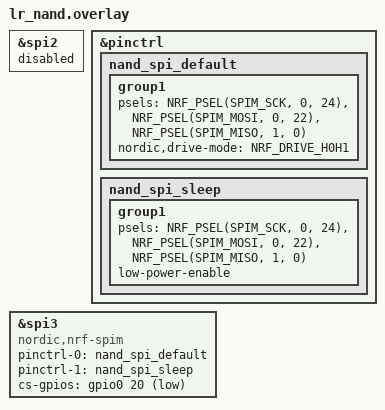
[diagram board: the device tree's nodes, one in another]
/* CONFIG_LR_NAND boards (LR-N5, LR-N5-S; a ProMicro on a breadboard for tests): a bare SPI NAND, W25N01GV or
 * W25N02KV (WSON-8 8x6), in place of the SD card, applied after the board's overlays (docs/nand-store.md 8, 11).
 * The chip on SPIM3 (EasyDMA, up to 32 MHz; SPIM0-2 stop at 8), on the SD card's four pins until the N5 pin plan
 * settles: CS P0.20, MOSI (DI) P0.22, SCK P0.24, MISO (DO) P1.00, all full-speed pins. SCK and MOSI at high drive
 * (H0H1): the nRF52840 PS asks for it above 8 MHz. Its supply: the SD card's LDO (sd-pwr-gpios, nand_card.c). */
/delete-node/ &sdhc0;
&spi2 { status = "disabled"; };

&pinctrl {
	nand_spi_default: nand_spi_default {
		group1 {
			psels = <NRF_PSEL(SPIM_SCK, 0, 24)>,
				<NRF_PSEL(SPIM_MOSI, 0, 22)>,
				<NRF_PSEL(SPIM_MISO, 1, 0)>;
			nordic,drive-mode = <NRF_DRIVE_H0H1>;
		};
	};
	nand_spi_sleep: nand_spi_sleep {
		group1 {
			psels = <NRF_PSEL(SPIM_SCK, 0, 24)>,
				<NRF_PSEL(SPIM_MOSI, 0, 22)>,
				<NRF_PSEL(SPIM_MISO, 1, 0)>;
			low-power-enable;
		};
	};
};

&spi3 {
	compatible = "nordic,nrf-spim";
	status = "okay";
	pinctrl-0 = <&nand_spi_default>;
	pinctrl-1 = <&nand_spi_sleep>;
	pinctrl-names = "default", "sleep";
	cs-gpios = <&gpio0 20 (GPIO_ACTIVE_LOW | NRF_GPIO_DRIVE_H0H1)>;
};
